AUTOSAR XML (schema 00051)
package /Tier1/ARPlatform1/Pcpt_CMscC  # Composit of modeling show case C
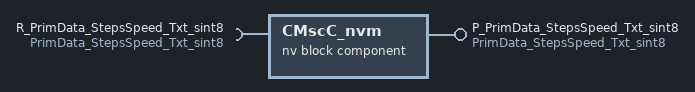
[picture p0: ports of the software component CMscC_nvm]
  nv block sw component type CMscC_nvm  # Composit of modeling show case C
    provide port P_PrimData_StepsSpeed_Txt_sint8: provided-interface=PrimData_StepsSpeed_Txt_sint8  # Stepwise speed indication
    require port R_PrimData_StepsSpeed_Txt_sint8: required-interface=PrimData_StepsSpeed_Txt_sint8  # Stepwise speed indication
    behavior CMscC_nvm: data-type-mapping=DefaultDataTypeMapping, handle-termination-and-restart=NO-SUPPORT
    nv block descriptor NvBlockA: data-type-mapping=DefaultDataTypeMapping, nv-block-data-mapping{nv-ram-block-element=NvBlockA_RamBlock.PrimData_StepsSpeed_Txt_sint8, read-nv-data=P_PrimData_StepsSpeed_Txt_sint8.PrimData_StepsSpeed_Txt_sint8, written-nv-data=R_PrimData_StepsSpeed_Txt_sint8.PrimData_StepsSpeed_Txt_sint8}  # NvBlock of egg cooking time determination
      nv block needs NvBlockA: calc-ram-block-crc=true, check-static-block-id=false, n-data-sets=0, n-rom-blocks=0, readonly=false, reliability=ERROR-DETECTION, resistant-to-changed-sw=false, restore-at-start=true, store-at-shutdown=true, write-only-once=false, writing-frequency=1000, writing-priority=LOW
      ram block NvBlockA_RamBlock: sw-addr-method=DATA_NVDAT, type=CMscC_nvm_NvBlockATyp
      rom block NvBlockA_RomBlock: sw-addr-method=CONST_SLOW, type=CMscC_nvm_NvBlockATyp, init-value=constant-reference=CMscC_nvm_NvBlockA_Impl
  swc implementation CMscC_nvm_impl: programming-language=C, vendor-id=8, behavior=CMscC_nvm
  collection CMscC_RequiredSwSystemConsts: category=SET, element=ScNoOfWheels
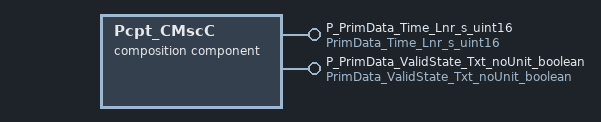
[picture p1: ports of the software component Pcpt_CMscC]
  composition sw component type Pcpt_CMscC: data-type-mapping=DefaultDataTypeMapping  # Composit of modeling show case C
    provide port P_PrimData_Time_Lnr_s_uint16: provided-interface=PrimData_Time_Lnr_s_uint16  # Primitve data holding a time value.
    provide port P_PrimData_ValidState_Txt_noUnit_boolean: provided-interface=PrimData_ValidState_Txt_noUnit_boolean  # Boolean representing the data validity
    4 x component:
      CMscA: type=Pcpt_CMscA
      CMscB: type=Pcpt_CMscB
      CMscC_nvm: type=CMscC_nvm
      CMscD: type=Pcpt_CMscD
    connect CMscA.P_ModeDirection -> CMscB.R_ModeDirection
    connect CMscA.P_PrimData_Mass_Lnr_Kg_uint8 -> CMscB.R_PrimData_Mass_Lnr_Kg_uint8
    connect CMscA.P_PrimData_StepsSpeed_Txt_sint8 -> CMscC_nvm.R_PrimData_StepsSpeed_Txt_sint8
    connect CMscA.P_PrimData_Temperature_Lin_K_C_uint16 -> CMscB.R_PrimData_Temperature_Lin_K_C_uint16
    connect CMscB.P_ComAxis_Mass_Lnr_Kg_uint8 -> CMscD.R_ComAxis_Mass_Lnr_Kg_uint8
    connect CMscB.P_PrimData_MassCorrected_Lnr_Kg_uint8 -> CMscD.R_PrimData_MassCorrected_Lnr_Kg_uint8
    delegate CMscB.P_PrimData_Time_Lnr_s_uint16 <-> outer port P_PrimData_Time_Lnr_s_uint16
    delegate CMscB.P_PrimData_ValidState_Txt_noUnit_boolean <-> outer port P_PrimData_ValidState_Txt_noUnit_boolean
    connect CMscC_nvm.P_PrimData_StepsSpeed_Txt_sint8 -> CMscA.R_PrimData_StepsSpeed_Txt_sint8
    connect CMscC_nvm.P_PrimData_StepsSpeed_Txt_sint8 -> CMscB.R_PrimData_StepsSpeed_Txt_sint8
package /Tier1/ARPlatform1/Pcpt_CMscC/ConstantSpecifications
  constant specification CMscC_nvm_NvBlockA_Impl: value-spec=fields=0
